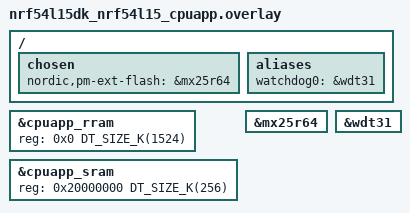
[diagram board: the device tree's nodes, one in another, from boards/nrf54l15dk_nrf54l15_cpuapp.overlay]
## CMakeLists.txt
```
cmake_minimum_required(VERSION 3.20.0)

find_package(Zephyr HINTS $ENV{ZEPHYR_BASE})

project(matter_multisensor)

# Enable GNU STD support.
include(${ZEPHYR_CONNECTEDHOMEIP_MODULE_DIR}/config/nrfconnect/app/enable-gnu-std.cmake)

# NORDIC SDK APP START

# Include all source files that are located in the Matter common directory.
include(${ZEPHYR_NRF_MODULE_DIR}/samples/matter/common/cmake/source_common.cmake)

# Include Data Model utils
include(${ZEPHYR_NRF_MODULE_DIR}/samples/matter/common/cmake/data_model.cmake)

include(${ZEPHYR_NRF_MODULE_DIR}/samples/matter/common/cmake/zap_helpers.cmake)
ncs_get_zap_parent_dir(ZAP_PARENT_DIR)

target_include_directories(app PRIVATE
  src
  src/domain
  src/ports
  src/usecases
  src/adapters
  ${ZEPHYR_NRF_MODULE_DIR}/samples/matter/common/src/board
  ${ZEPHYR_NRF_MODULE_DIR}/samples/matter/common/src/app
  ${ZEPHYR_NRF_MODULE_DIR}/samples/matter/common/src/clusters
  ${ZAP_PARENT_DIR}
)

target_sources(app PRIVATE
  src/domain/contact_sensors_domain.h
  src/domain/contact_sensors_domain.cpp
  src/domain/temperature_humidity_domain.h
  src/domain/temperature_humidity_domain.cpp
  src/ports/contact_sensor_input_port.h
  src/ports/contact_sensor_observer.h
  src/ports/temperature_humidity_input_port.h
  src/ports/temperature_humidity_observer.h
  src/ports/thread_network_reset_input_port.h
  src/ports/thread_network_reset_output_port.h
  src/usecases/toggle_contact_sensor_use_case.h
  src/usecases/toggle_contact_sensor_use_case.cpp
  src/usecases/update_temperature_humidity_use_case.h
  src/usecases/update_temperature_humidity_use_case.cpp
  src/usecases/reset_thread_network_use_case.h
  src/usecases/reset_thread_network_use_case.cpp
  src/adapters/button_adapter.h
  src/adapters/button_adapter.cpp
  src/adapters/placeholder_temperature_humidity_sensor_adapter.h
  src/adapters/placeholder_temperature_humidity_sensor_adapter.cpp
  src/adapters/matter_thread_adapter.h
  src/adapters/matter_thread_adapter.cpp
  src/main.cpp
)

ncs_configure_data_model()
# NORDIC SDK APP END
```

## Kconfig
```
mainmenu "Matter nRF Multisensor Application"

# Always-on, router-capable Thread device (Full Thread Device): the radio receiver stays on, so
# the device can act as a Thread router and answer controllers at any time.
if OPENTHREAD

choice OPENTHREAD_NORDIC_LIBRARY_CONFIGURATION
	default OPENTHREAD_NORDIC_LIBRARY_FTD
endchoice

choice OPENTHREAD_DEVICE_TYPE
	default OPENTHREAD_FTD
endchoice

endif # OPENTHREAD

config APP_TEMPERATURE_HUMIDITY_SAMPLE_PERIOD_S
	int "Temperature/humidity sensor sample period [s]"
	default 1
	range 1 3600
	help
	  How often the temperature/humidity sensor is read and published on Matter endpoints
	  4 and 5. The sensor is a placeholder producing made-up values until the part is chosen.

source "$(ZEPHYR_CONNECTEDHOMEIP_MODULE_DIR)/config/nrfconnect/chip-module/Kconfig.features"
source "$(ZEPHYR_CONNECTEDHOMEIP_MODULE_DIR)/config/nrfconnect/chip-module/Kconfig.defaults"
source "$(ZEPHYR_NRF_MODULE_DIR)/samples/matter/common/src/Kconfig"
source "Kconfig.zephyr"
```

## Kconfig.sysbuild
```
#
# Copyright (c) 2025 Nordic Semiconductor ASA
#
# SPDX-License-Identifier: LicenseRef-Nordic-5-Clause
#

#### Bootloader
choice BOOTLOADER
	default BOOTLOADER_MCUBOOT
endchoice

if BOOTLOADER_MCUBOOT

#### DFU multi-image support
config DFU_MULTI_IMAGE_PACKAGE_BUILD
	default y

config DFU_MULTI_IMAGE_PACKAGE_APP
	default y

config PM_EXTERNAL_FLASH_MCUBOOT_SECONDARY
	default y

# Disable checking the external drivers for the nRF54L15 DK.
config PM_OVERRIDE_EXTERNAL_DRIVER_CHECK
	default y

endif # BOOTLOADER_MCUBOOT

#### Enable generating factory data
config MATTER_FACTORY_DATA_GENERATE
	default y

source "share/sysbuild/Kconfig"
```

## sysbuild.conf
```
SB_CONFIG_MATTER=y

# Generate the Matter factory data partition (CONFIG_CHIP_FACTORY_DATA in prj.conf) and merge it
# into the flashed image, so `west flash` always programs the device identity together with the
# firmware. MATTER_FACTORY_DATA_GENERATE is also defaulted in Kconfig.sysbuild; both are spelled out
# here so the flashing behavior doesn't depend on SDK defaults.
SB_CONFIG_MATTER_FACTORY_DATA_GENERATE=y
SB_CONFIG_MATTER_FACTORY_DATA_MERGE_WITH_FIRMWARE=y
```

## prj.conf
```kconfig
#
# Copyright (c) 2025 Nordic Semiconductor ASA
#
# SPDX-License-Identifier: LicenseRef-Nordic-5-Clause
#

# Enable CHIP
CONFIG_CHIP=y

# Configure ZAP file name
CONFIG_NCS_SAMPLE_MATTER_ZAP_FILE_PATH="${APPLICATION_CONFIG_DIR}/matter_endpoint_zap/multisensor.zap"

CONFIG_STD_CPP17=y

# Enable Matter pairing automatically on application start.
CONFIG_CHIP_ENABLE_PAIRING_AUTOSTART=y

# Enable Matter extended announcement and increase duration to 1 hour.
CONFIG_CHIP_BLE_EXT_ADVERTISING=y
CONFIG_CHIP_BLE_ADVERTISING_DURATION=60

# Add support for LEDs and buttons on Nordic development kits
CONFIG_DK_LIBRARY=y

# Bluetooth Low Energy configuration
CONFIG_BT_DEVICE_NAME="MatterMultisensor"
CONFIG_BT_DEVICE_NAME_MAX=18

# Suspend devices when the CPU goes into sleep
CONFIG_PM_DEVICE=y

# Let idle-capable drivers (e.g. the external QSPI flash) auto-suspend between accesses, since
# system-level CONFIG_PM isn't available for this SoC yet.
CONFIG_PM_DEVICE_RUNTIME=y

# Other settings
CONFIG_THREAD_NAME=y
CONFIG_MPU_STACK_GUARD=y
CONFIG_RESET_ON_FATAL_ERROR=n
CONFIG_CHIP_LIB_SHELL=y

# Reduce application size
CONFIG_USE_SEGGER_RTT=n

# Enable Factory Data feature: the device identity below is not compiled into the firmware - it is
# generated into the separate `factory_data` flash partition (pm_static_*.yml) by the sysbuild
# `matter_factory_data` image, merged with the firmware and programmed by `west flash`. At runtime
# the Basic Information cluster (VendorName, ProductName, SerialNumber, ...) reads it from there,
# so changing any of these values requires a rebuild AND a re-flash (see README.md: "Building and flashing").
CONFIG_CHIP_FACTORY_DATA=y
CONFIG_CHIP_FACTORY_DATA_BUILD=y

# Names shown by controllers/ecosystems during commissioning (Basic Information VendorName /
# ProductName). Factory data string fields are limited to 32 ASCII characters.
CONFIG_CHIP_DEVICE_VENDOR_NAME="WizzDEV"
CONFIG_CHIP_DEVICE_PRODUCT_NAME="Matter nRF Multisensor"

# 0xFFF1 test Vendor ID (SDK default) and 32768 == 0x8000 example Product ID (added temporarily,
# as there is no assigned PID on the following list:
# https://github.com/project-chip/connectedhomeip/blob/482e6fd03196a6de45465a90003947ef4b86e0b1/docs/examples/discussion/PID_allocation_for_example_apps.md).
# Must stay a VID/PID pair the attestation certificates cover: the default development DAC/PAI
# (CONFIG_CHIP_FACTORY_DATA_USE_DEFAULT_CERTS) are issued for 0xFFF1/0x8000.
CONFIG_CHIP_DEVICE_VENDOR_ID=65521
CONFIG_CHIP_DEVICE_PRODUCT_ID=32768

# Remaining factory data identity fields, kept at the SDK's development defaults. Every unit
# flashed from the same build shares them (incl. serial number and setup code) - give each unit
# its own values before producing more than one.
CONFIG_CHIP_DEVICE_SERIAL_NUMBER="11223344556677889900"
CONFIG_CHIP_DEVICE_MANUFACTURING_DATE="2022-01-01"
CONFIG_CHIP_DEVICE_HARDWARE_VERSION=0
CONFIG_CHIP_DEVICE_HARDWARE_VERSION_STRING="prerelease"
CONFIG_CHIP_DEVICE_DISCRIMINATOR=0xF00
CONFIG_CHIP_DEVICE_SPAKE2_PASSCODE=20202021
```

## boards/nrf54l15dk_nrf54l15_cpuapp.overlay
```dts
/*
 * Copyright (c) 2025 Nordic Semiconductor ASA
 *
 * SPDX-License-Identifier: LicenseRef-Nordic-5-Clause
 */

#include <samples/matter/nrf54l15_cpuapp_partitions.dtsi>

/ {
	chosen {
		nordic,pm-ext-flash = &mx25r64;
	};

	aliases {
		/* Use watchdog wdt31 as the application watchdog */
		watchdog0 = &wdt31;
	};
};

/* restore full RRAM and SRAM space - by default some parts are dedicated to FLRP */
&cpuapp_rram {
	reg = <0x0 DT_SIZE_K(1524)>;
};

&cpuapp_sram {
	reg = <0x20000000 DT_SIZE_K(256)>;
	ranges = <0x0 0x20000000 0x40000>;
};

&mx25r64 {
	status = "okay";
};

&wdt31 {
	status = "okay";
};
```

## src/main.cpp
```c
#include "button_adapter.h"
#include "contact_sensors_domain.h"
#include "matter_thread_adapter.h"
#include "placeholder_temperature_humidity_sensor_adapter.h"
#include "reset_thread_network_use_case.h"
#include "task_executor.h"
#include "temperature_humidity_domain.h"
#include "toggle_contact_sensor_use_case.h"
#include "update_temperature_humidity_use_case.h"

#include <cstdlib>
#include <zephyr/logging/log.h>

LOG_MODULE_REGISTER(app, CONFIG_CHIP_APP_LOG_LEVEL);  // NOLINT(cppcoreguidelines-avoid-non-const-global-variables)

int main()
{
    domain::ContactSensorsDomain contactSensorsDomain;
    usecases::ToggleContactSensorUseCase toggleContactSensorUseCase{contactSensorsDomain};

    domain::TemperatureHumidityDomain temperatureHumidityDomain;
    usecases::UpdateTemperatureHumidityUseCase updateTemperatureHumidityUseCase{temperatureHumidityDomain};

    adapters::MatterThreadAdapter matterThreadAdapter;
    usecases::ResetThreadNetworkUseCase resetThreadNetworkUseCase{matterThreadAdapter};

    toggleContactSensorUseCase.addObserver(matterThreadAdapter);
    updateTemperatureHumidityUseCase.addObserver(matterThreadAdapter);

    CHIP_ERROR err = matterThreadAdapter.init();
    if (err != CHIP_NO_ERROR)
    {
        LOG_ERR("Matter initialization failed: %" CHIP_ERROR_FORMAT, err.Format());
        return EXIT_FAILURE;
    }

    adapters::ButtonAdapter buttonAdapter;
    if (!buttonAdapter.init(toggleContactSensorUseCase, resetThreadNetworkUseCase))
    {
        return EXIT_FAILURE;
    }

    /* Synchronize the Matter clusters with the domains' initial state (every contact sensor Open,
     * temperature/humidity reading unknown) once the main loop is running, mirroring the deferral every button
     * signal and sensor reading goes through. Posted before the temperature/humidity sensor starts sampling, so
     * the first reading always lands after it. */
    Nrf::PostTask(
        [&toggleContactSensorUseCase, &updateTemperatureHumidityUseCase]
        {
            toggleContactSensorUseCase.notifyObserversOfCurrentState();
            updateTemperatureHumidityUseCase.notifyObserversOfCurrentState();
        });

    adapters::PlaceholderTemperatureHumiditySensorAdapter temperatureHumiditySensorAdapter;
    temperatureHumiditySensorAdapter.init(updateTemperatureHumidityUseCase);

    err = matterThreadAdapter.startServer();
    if (err != CHIP_NO_ERROR)
    {
        LOG_ERR("Matter server start failed: %" CHIP_ERROR_FORMAT, err.Format());
        return EXIT_FAILURE;
    }

    while (true)
    {
        Nrf::DispatchNextTask();
    }

    return EXIT_SUCCESS;
}
```
